# NUC1261AE_v1 register map
File version: 1.0
Registers are 32-bit, read-write, reset 0x0 unless marked. A register's access mark holds for its fields unless they carry their own. Offsets are from the block's base; [hi:lo] are bit positions; lines under a group give offsets from that group; {n}, {i} and the like mark numbered series; 'fields as' and 'values as' point back to an identical list.

## CLK — CLK Register Map
Base 0x50000200
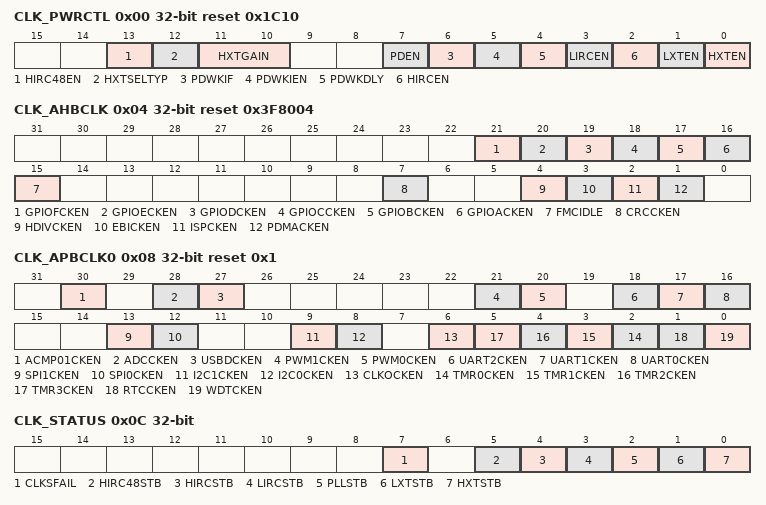
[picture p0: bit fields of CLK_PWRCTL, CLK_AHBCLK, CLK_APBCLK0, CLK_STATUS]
0x00 CLK_PWRCTL reset 0x1C10 (reset mask 0xFFFFFFF0) — System Power-down Control Register
  [13] HIRC48EN — HIRC48 Enable Bit (Write Protect). Note: This bit is write protected. Refer to the SYS_REGLCTL register.
    0=48 MHz internal high speed RC oscillator (HIRC48) Disabled; 1=48 MHz internal high speed RC oscillator (HIRC48) Enabled
  [12] HXTSELTYP — HXT Crystal Type Select Bit (Write Protect). This is a protected register. Please refer to open lock sequence to program it. Note: This bit is write protected. Refer to the SYS_REGLCTL register.
    0=Select INV type; 1=Select GM type
  [11:10] HXTGAIN — HXT Gain Control Bit (Write Protect). Gain control is used to enlarge the gain of crystal to make sure crystal work normally. If gain control is enabled, crystal will consume more power than gain control off. Note: This bit is write protected. Refer to the SYS_REGLCTL register.
    0=HXT frequency is lower than from 8 MHz; 1=HXT frequency is from 8 MHz to 12 MHz; 2=HXT frequency is from 12 MHz to 16 MHz; 3=HXT frequency is higher than 16 MHz
  [7] PDEN — System Power-down Enable (Write Protect). When this bit is set to 1, Power-down mode is enabled and chip keeps active till the CPU sleep mode is also active and then the chip enters Power-down mode. When chip wakes up from Power-down mode, this bit is auto cleared. Users need to set this bit again for next Power-down. In Power-down mode, HXT, HIRC and the HIRC48 will be disabled in this mode, but LXT and LIRC are not controlled by Power-down mode. In Power-down mode, the PLL and system clock are disabled, and ignored the clock source selection. The clocks of peripheral are not controlled by Power-down mode, if the peripheral clock source is from LXT or LIRC. Note: This bit is write protected. Refer to the SYS_REGLCTL register.
    0=Chip operating normally or chip in idle mode because of WFI command; 1=Chip waits CPU sleep command WFI and then enters Power-down mode
  [6] PDWKIF — Power-down Mode Wake-up Interrupt Status. Set by 'Power-down wake-up event', it indicates that resume from Power-down mode' The flag is set if the EINT0~5, GPIO, USBD, UART0~2, WDT, ACMP01, BOD, EBOD, RTC, TMR0~3, I2C0~1 or USCI0~2 wake-up occurred. Note1: This bit can be cleared by software writing '1'. Note2: This bit works only if PDWKIEN (CLK_PWRCTL[5]) set to 1.
  [5] PDWKIEN — Power-down Mode Wake-up Interrupt Enable Bit (Write Protect). Note1: The interrupt will occur when both PDWKIF and PDWKIEN are high. Note2: This bit is write protected. Refer to the SYS_REGLCTL register.
    0=Power-down mode wake-up interrupt Disabled; 1=Power-down mode wake-up interrupt Enabled
  [4] PDWKDLY — Enable the Wake-up Delay Counter (Write Protect). When the chip wakes up from Power-down mode, the clock control will delay certain clock cycles to wait system clock stable. The delayed clock cycle is 4096 clock cycles when chip work at 4~24 MHz external high speed crystal oscillator (HXT), 256 clock cycles when chip work at 22.1184 MHz internal high speed RC oscillator (HIRC) and 512 clock cycles when chip work at 48 MHz internal high speed RC oscillator (HIRC48). Note: This bit is write protected. Refer to the SYS_REGLCTL register.
    0=Clock cycles delay Disabled; 1=Clock cycles delay Enabled
  [3] LIRCEN — LIRC Enable Bit (Write Protect). Note: This bit is write protected. Refer to the SYS_REGLCTL register.
    0=10 kHz internal low speed RC oscillator (LIRC) Disabled; 1=10 kHz internal low speed RC oscillator (LIRC) Enabled
  [2] HIRCEN — HIRC Enable Bit (Write Protect). Note: This bit is write protected. Refer to the SYS_REGLCTL register.
    0=22.1184 MHz internal high speed RC oscillator (HIRC) Disabled; 1=22.1184 MHz internal high speed RC oscillator (HIRC) Enabled
  [1] LXTEN — LXT Enable Bit (Write Protect). Note: This bit is write protected. Refer to the SYS_REGLCTL register.
    0=32.768 kHz External Low Speed Crystal (LXT) Disabled; 1=32.768 kHz External Low Speed Crystal (LXT) Enabled
  [0] HXTEN — HXT Enable Bit (Write Protect). The bit default value is set by Flash controller user configuration register CONFIG0 [26:24]. When the default clock source is from HXT, this bit is set to 1 automatically. Note: This bit is write protected. Refer to the SYS_REGLCTL register.
    0=4~24 MHz External High Speed Crystal (HXT) Disabled; 1=4~24 MHz External High Speed Crystal (HXT) Enabled
0x04 CLK_AHBCLK reset 0x3F8004 — AHB Devices Clock Enable Control Register
  [21] GPIOFCKEN — General Purpose I/O PF Group Clock Enable Bit
    0=GPIO PF group clock Disabled; 1=GPIO PF group clock Enabled
  [20] GPIOECKEN — General Purpose I/O PE Group Clock Enable Bit
    0=GPIO PE group clock Disabled; 1=GPIO PE group clock Enabled
  [19] GPIODCKEN — General Purpose I/O PD Group Clock Enable Bit
    0=GPIO PD group clock Disabled; 1=GPIO PD group clock Enabled
  [18] GPIOCCKEN — General Purpose I/O PC Group Clock Enable Bit
    0=GPIO PC group clock Disabled; 1=GPIO PC group clock Enabled
  [17] GPIOBCKEN — General Purpose I/O PB Group Clock Enable Bit
    0=GPIO PB group clock Disabled; 1=GPIO PB group clock Enabled
  [16] GPIOACKEN — General Purpose I/O PA Group Clock Enable Bit
    0=GPIO PA group clock Disabled; 1=GPIO PA group clock Enabled
  [15] FMCIDLE — Flash Memory Controller Clock Enable Bit in IDLE Mode
    0=FMC peripheral clock Disabled when chip operating at IDLE mode; 1=FMC peripheral clock Enabled when chip operating at IDLE mode
  [7] CRCCKEN — CRC Generator Controller Clock Enable Bit
    0=CRC peripheral clock Disabled; 1=CRC peripheral clock Enabled
  [4] HDIVCKEN — Hardware Divider Controller Clock Enable Bit
    0=Hardware divider peripheral clock Disabled; 1=Hardware divider peripheral clock Enabled
  [3] EBICKEN — EBI Controller Clock Enable Bit
    0=EBI peripheral clock Disabled; 1=EBI peripheral clock Enabled
  [2] ISPCKEN — Flash ISP Controller Clock Enable Bit
    0=Flash ISP peripheral clock Disabled; 1=Flash ISP peripheral clock Enabled
  [1] PDMACKEN — PDMA Controller Clock Enable Bit
    0=PDMA peripheral clock Disabled; 1=PDMA peripheral clock Enabled
0x08 CLK_APBCLK0 reset 0x1 — APB Devices Clock Enable Control Register 0
  [30] ACMP01CKEN — Analog Comparator 0/1 Clock Enable Bit
    0=Analog Comparator 0/1 clock Disabled; 1=Analog Comparator 0/1 clock Enabled
  [28] ADCCKEN — Analog-digital-converter (ADC) Clock Enable Bit
    0=ADC clock Disabled; 1=ADC clock Enabled
  [27] USBDCKEN — USB Device Clock Enable Bit
    0=USB Device clock Disabled; 1=USB Device clock Enabled
  [21] PWM1CKEN — PWM1 Clock Enable Bit
    0=PWM1 clock Disabled; 1=PWM1 clock Enabled
  [20] PWM0CKEN — PWM0 Clock Enable Bit
    0=PWM0 clock Disabled; 1=PWM0 clock Enabled
  [18] UART2CKEN — UART2 Clock Enable Bit
    0=UART2 clock Disabled; 1=UART2 clock Enabled
  [17] UART1CKEN — UART1 Clock Enable Bit
    0=UART1 clock Disabled; 1=UART1 clock Enabled
  [16] UART0CKEN — UART0 Clock Enable Bit
    0=UART0 clock Disabled; 1=UART0 clock Enabled
  [13] SPI1CKEN — SPI1 Clock Enable Bit
    0=SPI1 Clock Disabled; 1=SPI1 Clock Enabled
  [12] SPI0CKEN — SPI0 Clock Enable Bit
    0=SPI0 Clock Disabled; 1=SPI0 Clock Enabled
  [9] I2C1CKEN — I2C1 Clock Enable Bit
    0=I2C1 Clock Disabled; 1=I2C1 Clock Enabled
  [8] I2C0CKEN — I2C0 Clock Enable Bit
    0=I2C0 Clock Disabled; 1=I2C0 Clock Enabled
  [6] CLKOCKEN — CLKO Clock Enable Bit
    0=CLKO Clock Disabled; 1=CLKO Clock Enabled
  [n+2] TMR{n}CKEN (n=0..3) — Timer{n} Clock Enable Bit
    0=Timer{n} Clock Disabled; 1=Timer{n} Clock Enabled
  [1] RTCCKEN — Real-time-clock APB Interface Clock Enable Bit. This bit is used to control the RTC APB clock only. The RTC peripheral clock source is selected from RTCSEL(CLK_CLKSEL2[18]). It can be selected to external 32.768 kHz low speed crystal (LXT) or 10 kHz internal low speed RC oscillator (LIRC).
    0=RTC Clock Disabled; 1=RTC Clock Enabled
  [0] WDTCKEN — Watchdog Timer Clock Enable Bit (Write Protect). Note: This bit is write protected. Refer to the SYS_REGLCTL register.
    0=Watchdog Timer Clock Disabled; 1=Watchdog Timer Clock Enabled
0x0C CLK_STATUS ro (reset mask 0xFFFFFF00) — Clock Status Monitor Register
  [7] CLKSFAIL — Clock Switching Fail Flag (Read Only). This bit is updated when software switches system clock source. If switch target clock is stable, this bit will be set to 0. If switch target clock is not stable, this bit will be set to 1. Note: After selected clock source is stable, hardware will switch system clock to selected clock automatically, and CLKSFAIL will be cleared automatically by hardware.
    0=Clock switching success; 1=Clock switching failure
  [5] HIRC48STB — HIRC48 Clock Source Stable Flag (Read Only)
    0=48 MHz internal high speed RC oscillator (HIRC48) clock is not stable or disabled; 1=48 MHz internal high speed RC oscillator (HIRC48) clock is stabe and enabled
  [4] HIRCSTB — HIRC Clock Source Stable Flag (Read Only)
    0=22.1184 MHz internal high speed RC oscillator (HIRC) clock is not stable or disabled; 1=22.1184 MHz internal high speed RC oscillator (HIRC) clock is stabe and enabled
  [3] LIRCSTB — LIRC Clock Source Stable Flag (Read Only)
    0=10 kHz internal low speed RC oscillator (LIRC) clock is not stable or disabled; 1=10 kHz internal low speed RC oscillator (LIRC) clock is stable and enabled
  [2] PLLSTB — Internal PLL Clock Source Stable Flag (Read Only)
    0=Internal PLL clock is not stable or disabled; 1=Internal PLL clock is stable and enabled
  [1] LXTSTB — LXT Clock Source Stable Flag (Read Only)
    0=32.768 kHz external low speed crystal oscillator (LXT) clock is not stable or disabled; 1=32.768 kHz external low speed crystal oscillator (LXT) clock is stabled and enabled
  [0] HXTSTB — HXT Clock Source Stable Flag (Read Only)
    0=4~24 MHz external high speed crystal oscillator (HXT) clock is not stable or disabled; 1=4~24 MHz external high speed crystal oscillator (HXT)clock is stable and enabled
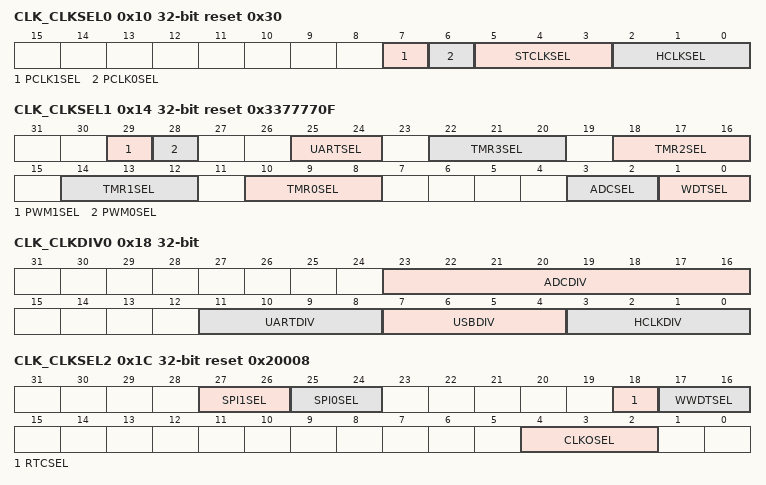
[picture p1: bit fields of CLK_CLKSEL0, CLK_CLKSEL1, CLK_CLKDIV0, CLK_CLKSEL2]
0x10 CLK_CLKSEL0 reset 0x30 (reset mask 0xFFFFFFF0) — Clock Source Select Control Register 0
  [7] PCLK1SEL — PCLK1 Clock Source Selection (Write Protect). Note: This bit is write protected. Refer to the SYS_REGLCTL register.
    0=APB1 BUS clock source from HCLK; 1=APB1 BUS clock source from HCLK/2
  [6] PCLK0SEL — PCLK0 Clock Source Selection (Write Protect). Note: This bit is write protected. Refer to the SYS_REGLCTL register.
    0=APB0 BUS clock source from HCLK; 1=APB0 BUS clock source from HCLK/2
  [5:3] STCLKSEL — Cortex-M0 SysTick Clock Source Selection (Write Protect). Note2: These bits are write protected. Refer to the SYS_REGLCTL register.
    0=Clock source from HXT; 1=Clock source from LXT; 2=Clock source from HXT/2; 3=Clock source from HCLK/2; 7=Clock source from HIRC/2
  [2:0] HCLKSEL — HCLK Clock Source Selection (Write Protect). Before clock switching, the related clock sources (both pre-select and new-select) must be turned on. The default value is reloaded from the value of CFOSC (CONFIG0[26:24]) in user configuration register of Flash controller by any reset. Therefore the default value is either 000b or 111b. Note: These bits are write protected. Refer to the SYS_REGLCTL register.
    0=Clock source from HXT; 1=Clock source from LXT; 2=Clock source from PLL clock; 3=Clock source from LIRC; 4=Clock source from HIRC48.Reserved; 7=Clock source from HIRC clock
0x14 CLK_CLKSEL1 reset 0x3377770F — Clock Source Select Control Register 1
  [29] PWM1SEL — PWM1 Clock Source Selection. The peripheral clock source of PWM1 is defined by PWM1SEL.
    0=Clock source from PLL clock; 1=Clock source from PCLK1
  [28] PWM0SEL — PWM0 Clock Source Selection. The peripheral clock source of PWM0 is defined by PWM0SEL.
    0=Clock source from PLL clock; 1=Clock source from PCLK0
  [25:24] UARTSEL — UART Clock Source Selection
    0=Clock source from 4~24 MHz external high speed crystal oscillator (HXT) clock; 1=Clock source from PLL clock; 2=Clock source from 32.768 kHz external low speed crystal oscillator (LXT) clock; 3=Clock source from 22.1184 MHz internal high speed RC oscillator (HIRC) clock
  [22:20] TMR3SEL — TIMER3 Clock Source Selection
    0=Clock source from 4~24 MHz external high speed crystal oscillator (HXT) clock; 1=Clock source from 32.768 kHz external low speed crystal oscillator (LXT) clock; 2=Clock source from PCLK1; 3=Clock source from external clock T3 pin; 5=Clock source from 10 kHz internal low speed RC oscillator (LIRC) clock; 7=Clock source from 22.1184 MHz internal high speed RC oscillator (HIRC) clock
  [18:16] TMR2SEL — TIMER2 Clock Source Selection
    0=Clock source from 4~24 MHz external high speed crystal oscillator (HXT) clock; 1=Clock source from 32.768 kHz external low speed crystal oscillator (LXT) clock; 2=Clock source from PCLK1; 3=Clock source from external clock T2 pin; 5=Clock source from 10 kHz internal low speed RC oscillator (LIRC) clock; 7=Clock source from 22.1184 MHz internal high speed RC oscillator (HIRC) clock
  [14:12] TMR1SEL — TIMER1 Clock Source Selection
    0=Clock source from 4~24 MHz external high speed crystal oscillator (HXT) clock; 1=Clock source from 32.768 kHz external low speed crystal oscillator (LXT) clock; 2=Clock source from PCLK0; 3=Clock source from external clock T1 pin; 5=Clock source from 10 kHz internal low speed RC oscillator (LIRC) clock; 7=Clock source from 22.1184 MHz internal high speed RC oscillator (HIRC) clock
  [10:8] TMR0SEL — TIMER0 Clock Source Selection
    0=Clock source from 4~24 MHz external high speed crystal oscillator (HXT) clock; 1=Clock source from 32.768 kHz external low speed crystal oscillator (LXT) clock; 2=Clock source from PCLK0; 3=Clock source from external clock T0 pin; 5=Clock source from 10 kHz internal low speed RC oscillator (LIRC) clock; 7=Clock source from 22.1184 MHz internal high speed RC oscillator (HIRC) clock
  [3:2] ADCSEL — ADC Clock Source Selection
    0=Clock source from 4~24 MHz external high speed crystal oscillator (HXT) clock; 1=Clock source from PLL; 2=Clock source from PCLK0; 3=Clock source from 22.1184 MHz internal high speed RC oscillator (HIRC) clock
  [1:0] WDTSEL — Watchdog Timer Clock Source Selection (Write Protect). Note: These bits are write protected. Refer to the SYS_REGLCTL register.
    1=Clock source from 32.768 kHz external low speed crystal oscillator (LXT) clock; 2=Clock source from HCLK/2048 clock; 3=Clock source from 10 kHz internal low speed RC oscillator (LIRC) clock
0x18 CLK_CLKDIV0 — Clock Divider Number Register 0
  [23:16] ADCDIV — ADC Clock Divide Number From ADC Clock Source
  [11:8] UARTDIV — UART Clock Divide Number From UART Clock Source
  [7:4] USBDIV — USB Clock Divide Number From PLL Source. Note: If the HIRC48 is selected, it is delivery to USB clock directly.
  [3:0] HCLKDIV — HCLK Clock Divide Number From HCLK Clock Source
0x1C CLK_CLKSEL2 reset 0x20008 — Clock Source Select Control Register 2
  [27:26] SPI1SEL — SPI1 Clock Source Selection
    0=Clock source from 4~24 MHz external high speed crystal oscillator (HXT) clock; 1=Clock source from PLL clock; 2=Clock source from PCLK0; 3=Clock source from 48 MHz internal high speed RC oscillator (HIRC48) clock
  [25:24] SPI0SEL — SPI0 Clock Source Selection
    values as SPI1SEL
  [18] RTCSEL — RTC Clock Source Selection
    0=Clock source from 32.768 kHz external low speed crystal oscillator (LXT); 1=Clock source from 10 kHz internal low speed RC oscillator (LIRC)
  [17:16] WWDTSEL — Window Watchdog Timer Clock Source Selection
    2=Clock source from HCLK/2048 clock; 3=Clock source from 10 kHz internal low speed RC oscillator (LIRC)
  [4:2] CLKOSEL — Clock Divider Clock Source Selection
    0=Clock source from 4~24 MHz external high speed crystal oscillator (HXT) clock; 1=Clock source from 32.768 kHz external low speed crystal oscillator (LXT) clock; 2=Clock source from HCLK; 3=Clock source from 22.1184 MHz internal high speed RC oscillator (HIRC) clock; 4=Clock source from SOF (USB start of frame event); 5=Clock source from 48 MHz internal high speed RC oscillator (HIRC48) clock
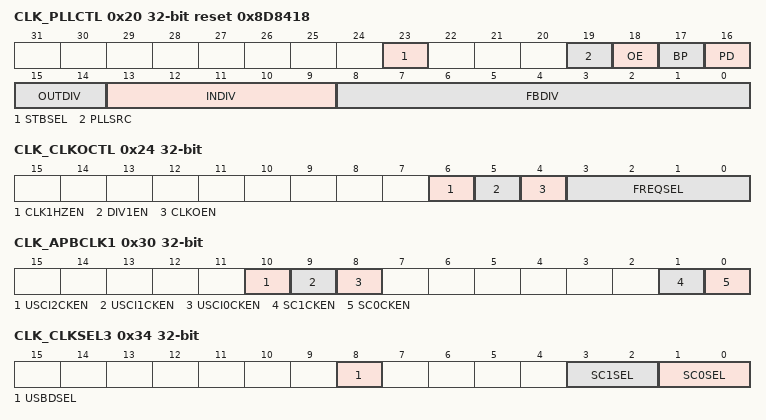
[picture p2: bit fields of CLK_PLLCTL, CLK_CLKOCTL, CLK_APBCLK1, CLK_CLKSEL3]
0x20 CLK_PLLCTL reset 0x8D8418 — PLL Control Register
  [23] STBSEL — PLL Stable Counter Selection
    0=PLL stable time is 6144 PLL source clock (suitable for source clock is equal to or less than 12 MHz); 1=PLL stable time is 12288 PLL source clock (suitable for source clock is larger than 12 MHz)
  [19] PLLSRC — PLL Source Clock Selection
    0=PLL source clock from external 4~24 MHz high-speed crystal (HXT); 1=PLL source clock from internal 22.1184 MHz high-speed oscillator (HIRC)
  [18] OE — PLL OE (FOUT Enable) Control
    0=PLL FOUT Enabled; 1=PLL FOUT is fixed low
  [17] BP — PLL Bypass Control
    0=PLL is in normal mode (default); 1=PLL clock output is same as PLL input clock FIN
  [16] PD — Power-down Mode. If set PDEN(CLK_PWRCTL[7]) bit to 1, the PLL will enter Power-down mode, too.
    0=PLL is in normal mode; 1=PLL is in Power-down mode (default)
  [15:14] OUTDIV — PLL Output Divider Control. Refer to the formulas below the table.
  [13:9] INDIV — PLL Input Divider Control. Refer to the formulas below the table.
  [8:0] FBDIV — PLL Feedback Divider Control. Refer to the formulas below the table.
0x24 CLK_CLKOCTL — Clock Output Control Register
  [6] CLK1HZEN — Clock Output 1Hz Enable Bit
    0=1 Hz clock output for 32.768 kHz external low speed crystal oscillator (LXT) frequency compensation Disabled; 1=1 Hz clock output for 32.768 kHz external low speed crystal oscillator (LXT) frequency compensation Enabled
  [5] DIV1EN — Clock Output Divide One Enable Bit
    0=Clock Output will output clock with source frequency divided by FREQSEL; 1=Clock Output will output clock with source frequency
  [4] CLKOEN — Clock Output Enable Bit
    0=Clock Output function Disabled; 1=Clock Output function Enabled
  [3:0] FREQSEL — Clock Output Frequency Selection. The formula of output frequency is. Fin is the input clock frequency. Fout is the frequency of divider output clock. N is the 4-bit value of FREQSEL[3:0].
0x30 CLK_APBCLK1 — APB Devices Clock Enable Control Register 1
  [10] USCI2CKEN — USCI2 Clock Enable Bit
    0=USCI2 clock Disabled; 1=USCI2 clock Enabled
  [9] USCI1CKEN — USCI1 Clock Enable Bit
    0=USCI1 clock Disabled; 1=USCI1 clock Enabled
  [8] USCI0CKEN — USCI0 Clock Enable Bit
    0=USCI0 clock Disabled; 1=USCI0 clock Enabled
  [1] SC1CKEN — SC1 Clock Enable Bit
    0=SC1 clock Disabled; 1=SC1 clock Enabled
  [0] SC0CKEN — SC0 Clock Enable Bit
    0=SC0 Clock Disabled; 1=SC0 Clock Enabled
0x34 CLK_CLKSEL3 — Clock Source Select Control Register 3
  [8] USBDSEL — USBD Clock Source Selection(Write Protect). Note: This bit is write protected. Refer to the SYS_REGLCTL register.
    0=Clock source from 48 MHz internal hight speed RC oscillator (HIRC48) clock; 1=Clock source from PLL clock
  [3:2] SC1SEL — SC1 Clock Source Selection
    0=Clock source from 4~24 MHz external high speed crystal oscillator (HXT) clock; 1=Clock source from PLL clock; 2=Clock source from PCLK1; 3=Clock source from 22.1184 MHz internal high speed RC oscillator (HIRC) clock
  [1:0] SC0SEL — SC0 Clock Source Selection
    0=Clock source from 4~24 MHz external high speed crystal oscillato r(HXT) clock; 1=Clock source from PLL clock; 2=Clock source from PCLK1; 3=Clock source from 22.1184 MHz internal high speed RC oscillator (HIRC) clock
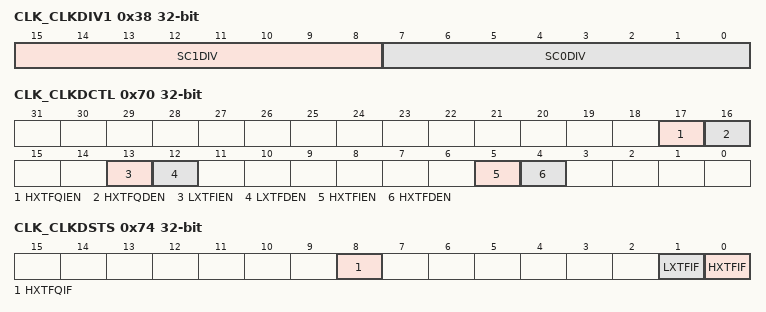
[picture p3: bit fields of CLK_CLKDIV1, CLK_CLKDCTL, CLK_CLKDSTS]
0x38 CLK_CLKDIV1 — Clock Divider Number Register 1
  [15:8] SC1DIV — SC1 Clock Divide Number From SC1 Clock Source
  [7:0] SC0DIV — SC0 Clock Divide Number From SC0 Clock Source
0x40 CLK_BODCLK — Clock Source Select for BOD Control Register
  [0] VDETCKSEL — Clock Source Selection for Voltage Detector. The Voltage Detector clock source for detecting external input voltage is defined by VDETCKSEL. Note1: If LIRC is selected, LIRCEN (CLK_PWRCTL[3]) must be enabled. Note2: If LXT is selected, LXTEN (CLK_PWRCTL[1]) must be enabled.
    0=Clock source is from 10 kHz internal low speed RC oscillator (LIRC) clock; 1=Clock source is from 32.768 kHz external low speed crystal oscillator (LXT) clock
0x70 CLK_CLKDCTL — Clock Fail Detector Control Register
  [17] HXTFQIEN — HXT Clock Frequency Monitor Interrupt Enable Bit
    0=4~24 MHz external high speed crystal oscillator (HXT) clock frequency monitor fail interrupt Disabled; 1=4~24 MHz external high speed crystal oscillator (HXT) clock frequency monitor fail interrupt Enabled
  [16] HXTFQDEN — HXT Clock Frequency Monitor Enable Bit
    0=4~24 MHz external high speed crystal oscillator (HXT) clock frequency monitor Disabled; 1=4~24 MHz external high speed crystal oscillator (HXT) clock frequency monitor Enabled
  [13] LXTFIEN — LXT Clock Fail Interrupt Enable Bit
    0=32.768 kHz external low speed crystal oscillator (LXT) clock Fail interrupt Disabled; 1=32.768 kHz external low speed crystal oscillator (LXT) clock Fail interrupt Enabled
  [12] LXTFDEN — LXT Clock Fail Detector Enable Bit
    0=32.768 kHz external low speed crystal oscillator (LXT) clock Fail detector Disabled; 1=32.768 kHz external low speed crystal oscillator (LXT) clock Fail detector Enabled
  [5] HXTFIEN — HXT Clock Fail Interrupt Enable Bit
    0=4~24 MHz external high speed crystal oscillator (HXT)clock Fail interrupt Disabled; 1=4~24 MHz external high speed crystal oscillator (HXT)clock Fail interrupt Enabled
  [4] HXTFDEN — HXT Clock Fail Detector Enable Bit
    0=4~24 MHz external high speed crystal oscillator (HXT) clock Fail detector Disabled; 1=4~24 MHz external high speed crystal oscillator (HXT) clock Fail detector Enabled
0x74 CLK_CLKDSTS — Clock Fail Detector Status Register
  [8] HXTFQIF — HXT Clock Frequency Monitor Interrupt Flag (Write Protect). Note1: This bit can be cleared to 0 by software writing '1'. Note2: This bit is write protected. Refer to the SYS_REGLCTL register.
    0=4~24 MHz external high speed crystal oscillator (HXT) clock normal; 1=4~24 MHz external high speed crystal oscillator (HXT) clock frequency abnormal
  [1] LXTFIF — LXT Clock Fail Interrupt Flag (Write Protect). Note1: This bit can be cleared to 0 by software writing '1'. Note2: This bit is write protected. Refer to the SYS_REGLCTL register.
    0=32.768 kHz external low speed crystal oscillator (LXT) clock normal; 1=32.768 kHz external low speed crystal oscillator (LXT) stop
  [0] HXTFIF — HXT Clock Fail Interrupt Flag (Write Protect). Note1: This bit can be cleared to 0 by software writing '1'. Note2: This bit is write protected. Refer to the SYS_REGLCTL register.
    0=4~24 MHz external high speed crystal oscillator (HXT) clock normal; 1=4~24 MHz external high speed crystal oscillator (HXT) clock stop
0x78 CLK_CDUPB — Clock Frequency Detector Upper Boundary Register
  [9:0] UPERBD — HXT Clock Frequency Detector Upper Boundary. The bits define the high value of frequency monitor window. When HXT frequency monitor value higher than this register, the HXT frequency detect fail interrupt flag will set to 1.
0x7C CLK_CDLOWB — Clock Frequency Detector Low Boundary Register
  [9:0] LOWERBD — HXT Clock Frequency Detector Low Boundary. The bits define the low value of frequency monitor window. When HXT frequency monitor value lower than this register, the HXT frequency detect fail interrupt flag will set to 1.
